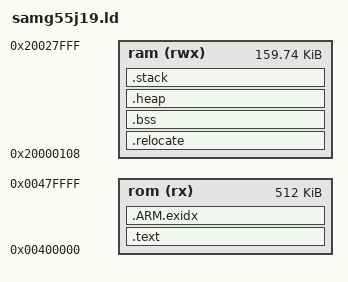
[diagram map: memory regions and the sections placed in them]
OUTPUT_FORMAT("elf32-littlearm", "elf32-littlearm", "elf32-littlearm")
OUTPUT_ARCH(arm)
SEARCH_DIR(.)

#if !defined(MBED_BOOT_STACK_SIZE)
    #define MBED_BOOT_STACK_SIZE 0x400
#endif

STACK_SIZE = MBED_BOOT_STACK_SIZE;

/* Memory Spaces Definitions */
MEMORY {
    rom (rx)  : ORIGIN = 0x00400000, LENGTH = 0x00080000
        ram (rwx) : ORIGIN = 0x20000000 + 0x108, LENGTH = 0x00028000 - 0x108
    }

    /* Section Definitions */
    SECTIONS {
.text :
    {
        . = ALIGN(8);
        _sfixed = .;
        KEEP(*(.vectors .vectors.*))
        *(.text .text.* .gnu.linkonce.t.*)
        *(.glue_7t) *(.glue_7)
        *(.rodata .rodata* .gnu.linkonce.r.*)
        *(.ARM.extab* .gnu.linkonce.armextab.*)

        /* Support C constructors, and C destructors in both user code
           and the C library. This also provides support for C++ code. */
        . = ALIGN(8);
        KEEP(*(.init))
        . = ALIGN(8);
        __preinit_array_start = .;
        KEEP (*(.preinit_array))
        __preinit_array_end = .;

        . = ALIGN(8);
        __init_array_start = .;
        KEEP (*(SORT(.init_array.*)))
        KEEP (*(.init_array))
        __init_array_end = .;

        . = ALIGN(8);
        KEEP (*crtbegin.o(.ctors))
        KEEP (*(EXCLUDE_FILE (*crtend.o) .ctors))
        KEEP (*(SORT(.ctors.*)))
        KEEP (*crtend.o(.ctors))

        . = ALIGN(8);
        KEEP(*(.fini))

        . = ALIGN(8);
        __fini_array_start = .;
        KEEP (*(.fini_array))
        KEEP (*(SORT(.fini_array.*)))
        __fini_array_end = .;

        KEEP (*crtbegin.o(.dtors))
        KEEP (*(EXCLUDE_FILE (*crtend.o) .dtors))
        KEEP (*(SORT(.dtors.*)))
        KEEP (*crtend.o(.dtors))

        . = ALIGN(8);
        _efixed = .;            /* End of text section */
    } > rom

    /* .ARM.exidx is sorted, so has to go in its own output section.  */
    PROVIDE_HIDDEN (__exidx_start = .);
.ARM.exidx :
    {
        *(.ARM.exidx* .gnu.linkonce.armexidx.*)
    } > rom
    PROVIDE_HIDDEN (__exidx_end = .);

    . = ALIGN(8);
    _etext = .;

.relocate :
    AT (_etext)
    {
        . = ALIGN(8);
        _srelocate = .;
        *(.ramfunc .ramfunc.*);
        *(.data .data.*);
        . = ALIGN(8);
        _erelocate = .;
    } > ram

    /* .bss section which is used for uninitialized data */
    .bss (NOLOAD) :
    {
        . = ALIGN(8);
        _sbss = . ;
        _szero = .;
        *(.bss .bss.*)
        *(COMMON)
        . = ALIGN(8);
        _ebss = . ;
        _ezero = .;
    } > ram

    .heap (NOLOAD) :
    {
        . = ALIGN(8);
        __end__ = . ;
        . = ORIGIN(ram) + LENGTH(ram) - STACK_SIZE;
        __HeapLimit = .;
    } > ram

    /* stack section */
    .stack (NOLOAD):
    {
        . = ALIGN(8);
        _sstack = .;
        . = . + STACK_SIZE;
        . = ALIGN(8);
        _estack = .;
    } > ram
    
    /* Set stack top to end of RAM, and stack limit move down by
     * size of stack_dummy section */
    __StackTop = ORIGIN(RAM) + LENGTH(RAM);
    __StackLimit = __StackTop - STACK_SIZE;

    . = ALIGN(8);
}
